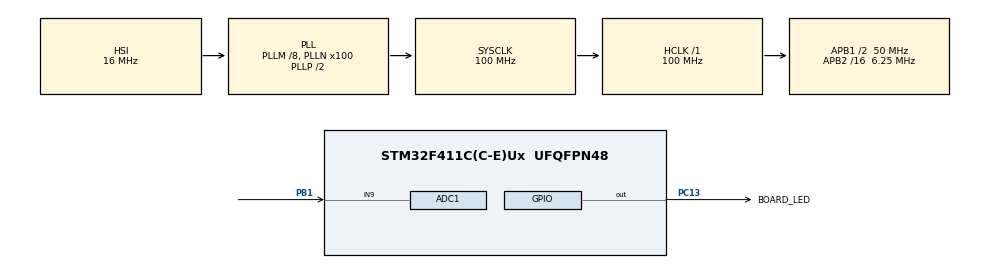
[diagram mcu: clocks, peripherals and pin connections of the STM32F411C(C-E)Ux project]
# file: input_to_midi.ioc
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ADC1.Channel-0\#ChannelRegularConversion=ADC_CHANNEL_9
ADC1.ClockPrescaler=ADC_CLOCK_SYNC_PCLK_DIV8
ADC1.ContinuousConvMode=ENABLE
ADC1.DMAContinuousRequests=ENABLE
ADC1.NbrOfConversion=1
ADC1.NbrOfConversionFlag=1
ADC1.Rank-0\#ChannelRegularConversion=1
ADC1.SamplingTime-0\#ChannelRegularConversion=ADC_SAMPLETIME_3CYCLES
ADC1.master=1
Dma.ADC1.0.Direction=DMA_PERIPH_TO_MEMORY
Dma.ADC1.0.FIFOMode=DMA_FIFOMODE_DISABLE
Dma.ADC1.0.Instance=DMA2_Stream0
Dma.ADC1.0.MemDataAlignment=DMA_MDATAALIGN_WORD
Dma.ADC1.0.MemInc=DMA_MINC_ENABLE
Dma.ADC1.0.Mode=DMA_CIRCULAR
Dma.ADC1.0.PeriphDataAlignment=DMA_PDATAALIGN_WORD
Dma.ADC1.0.PeriphInc=DMA_PINC_DISABLE
Dma.ADC1.0.Priority=DMA_PRIORITY_LOW
Dma.Request0=ADC1
Mcu.Family=STM32F4
Mcu.Name=STM32F411C(C-E)Ux
Mcu.Package=UFQFPN48
NVIC.DMA2_Stream0_IRQn=true\:0\:0\:false\:false\:true\:false\:true\:true
NVIC.PriorityGroup=NVIC_PRIORITYGROUP_4
PB1.Signal=ADCx_IN9
PC13-ANTI_TAMP.GPIO_Label=BOARD_LED
PC13-ANTI_TAMP.Signal=GPIO_Output
ProjectManager.HeapSize=0x200
ProjectManager.StackSize=0x400
ProjectManager.TargetToolchain=STM32CubeIDE
RCC.48MHZClocksFreq_Value=50000000
RCC.AHBFreq_Value=100000000
RCC.APB1CLKDivider=RCC_HCLK_DIV2
RCC.APB1Freq_Value=50000000
RCC.APB1TimFreq_Value=100000000
RCC.APB2CLKDivider=RCC_HCLK_DIV16
RCC.APB2Freq_Value=6250000
RCC.APB2TimFreq_Value=12500000
RCC.CortexFreq_Value=100000000
RCC.HCLKFreq_Value=100000000
RCC.HSE_VALUE=25000000
RCC.HSI_VALUE=16000000
RCC.LSE_VALUE=32768
RCC.PLLM=8
RCC.PLLN=100
RCC.SYSCLKFreq_VALUE=100000000
RCC.SYSCLKSource=RCC_SYSCLKSOURCE_PLLCLK
RCC.VCOOutputFreq_Value=200000000
SH.ADCx_IN9.0=ADC1_IN9,IN9
board=custom

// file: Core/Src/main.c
/* USER CODE BEGIN Header */
/**
  ******************************************************************************
  * @file           : main.c
  * @brief          : Main program body
  ******************************************************************************
  * @attention
  *
  * Copyright (c) 2024 STMicroelectronics.
  * All rights reserved.
  *
  * This software is licensed under terms that can be found in the LICENSE file
  * in the root directory of this software component.
  * If no LICENSE file comes with this software, it is provided AS-IS.
  *
  ******************************************************************************
  */
/* USER CODE END Header */
#include "main.h"
#include "adc.h"
#include "dma.h"
#include "gpio.h"

/* USER CODE BEGIN Includes */
#include "input_to_midi.h"

/* USER CODE END Includes */

void SystemClock_Config(void);

int main(void)
{

  /* MCU Configuration--------------------------------------------------------*/

  /* Reset of all peripherals, Initializes the Flash interface and the Systick. */
  HAL_Init();

  /* Configure the system clock */
  SystemClock_Config();

  /* Initialize all configured peripherals */
  MX_GPIO_Init();
  MX_DMA_Init();
  MX_ADC1_Init();
  /* USER CODE BEGIN 2 */

  input_to_midi_start();

  /* USER CODE END 2 */

  /* Infinite loop */
  /* USER CODE BEGIN WHILE */
  while (1)
  {
	  input_to_midi_loop();

    /* USER CODE END WHILE */

  }
}

void SystemClock_Config(void)
{
  RCC_OscInitTypeDef RCC_OscInitStruct = {0};
  RCC_ClkInitTypeDef RCC_ClkInitStruct = {0};

  /** Configure the main internal regulator output voltage
  */
  __HAL_RCC_PWR_CLK_ENABLE();
  __HAL_PWR_VOLTAGESCALING_CONFIG(PWR_REGULATOR_VOLTAGE_SCALE1);

  /** Initializes the RCC Oscillators according to the specified parameters
  * in the RCC_OscInitTypeDef structure.
  */
  RCC_OscInitStruct.OscillatorType = RCC_OSCILLATORTYPE_HSI;
  RCC_OscInitStruct.HSIState = RCC_HSI_ON;
  RCC_OscInitStruct.HSICalibrationValue = RCC_HSICALIBRATION_DEFAULT;
  RCC_OscInitStruct.PLL.PLLState = RCC_PLL_ON;
  RCC_OscInitStruct.PLL.PLLSource = RCC_PLLSOURCE_HSI;
  RCC_OscInitStruct.PLL.PLLM = 8;
  RCC_OscInitStruct.PLL.PLLN = 100;
  RCC_OscInitStruct.PLL.PLLP = RCC_PLLP_DIV2;
  RCC_OscInitStruct.PLL.PLLQ = 4;
  if (HAL_RCC_OscConfig(&RCC_OscInitStruct) != HAL_OK)
  {
    Error_Handler();
  }

  /** Initializes the CPU, AHB and APB buses clocks
  */
  RCC_ClkInitStruct.ClockType = RCC_CLOCKTYPE_HCLK|RCC_CLOCKTYPE_SYSCLK
                              |RCC_CLOCKTYPE_PCLK1|RCC_CLOCKTYPE_PCLK2;
  RCC_ClkInitStruct.SYSCLKSource = RCC_SYSCLKSOURCE_PLLCLK;
  RCC_ClkInitStruct.AHBCLKDivider = RCC_SYSCLK_DIV1;
  RCC_ClkInitStruct.APB1CLKDivider = RCC_HCLK_DIV2;
  RCC_ClkInitStruct.APB2CLKDivider = RCC_HCLK_DIV16;

  if (HAL_RCC_ClockConfig(&RCC_ClkInitStruct, FLASH_LATENCY_3) != HAL_OK)
  {
    Error_Handler();
  }
}

void Error_Handler(void)
{
  __disable_irq();
  while (1)
  {
  }
}
